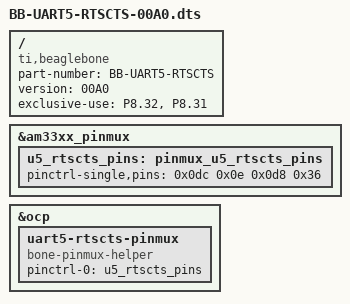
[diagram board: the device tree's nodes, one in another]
/*
 * Copyright 2018
 * Yantrr Electronic Systems Pvt. Ltd. - http://www.yantrr.com/
 *
 * BeagleBone cape RS485 / RS422 using UART5-RTSCTS connector pins P8.32 P8.31
 *
 * This program is free software: you can redistribute it and/or modify
 * it under the terms of the GNU General Public License as published by
 * the Free Software Foundation, either version 3 of the License, or 
 * (at your option) any later version.
 *
 * This program is distributed in the hope that it will be useful,
 * but WITHOUT ANY WARRANTY; without even the implied warranty of
 * MERCHANTABILITY or FITNESS FOR A PARTICULAR PURPOSE.  See the
 * GNU General Public License for more details.
 *
*/

/dts-v1/;
/plugin/;

/{
  compatible = "ti,beaglebone", "ti,beaglebone-black";

  part-number = "BB-UART5-RTSCTS";
  version = "00A0";

  exclusive-use =
    "P8.32",    // uart5_rtsn     conflict with HDMI pin
    "P8.31";    // uart5_ctsn     conflict with HDMI pin

  fragment@0 {
    /* Sets pinmux for flow control pins. */
    target = <&am33xx_pinmux>;
    __overlay__ {
      u5_rtscts_pins: pinmux_u5_rtscts_pins {
        pinctrl-single,pins = <
          0x0dc 0x0e      /* mode 6 (uart5_rtsn) */
          0x0d8 0x36      /* mode 6 (uart5_ctsn) */
        >;
      };
    };
  };

  fragment@1 {
    /* Enable pinmux-helper driver for setting mux configuration. */
    target = <&ocp>; /* On-Chip Peripherals */
    __overlay__ {
      uart5-rtscts-pinmux {
        compatible = "bone-pinmux-helper"; /* Use the pinmux helper */
        status="okay";
        /* Define custom names for indexes in pinctrl array: */
        pinctrl-names = "default";
        /* Set the elements of the pinctrl array to the pinmux overlays
           defined above: */
        pinctrl-0 = <&u5_rtscts_pins>;
      };
    };
  };
};
